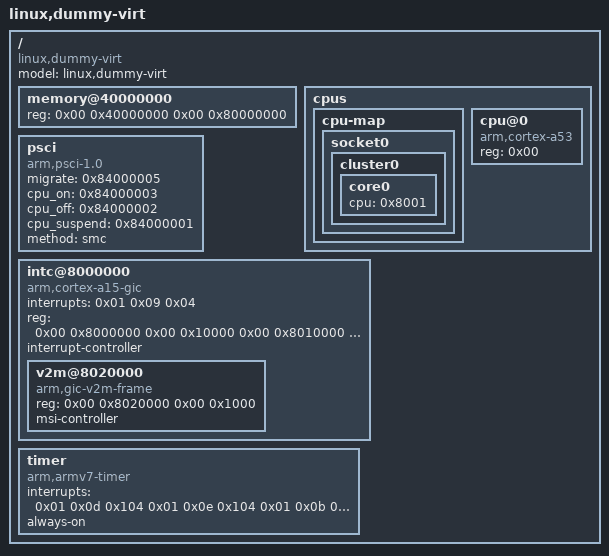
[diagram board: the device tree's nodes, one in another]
/dts-v1/;

/ {
	model = "linux,dummy-virt";
	compatible = "linux,dummy-virt";
	#size-cells = <0x02>;
	#address-cells = <0x02>;


	memory@40000000 {
		reg = <0x00 0x40000000 0x00 0x80000000>;
		device_type = "memory";
	};

	cpus {
		#size-cells = <0x00>;
		#address-cells = <0x01>;

		cpu-map {

			socket0 {

				cluster0 {

					core0 {
						cpu = <0x8001>;
					};
				};
			};
		};

		cpu@0 {
			phandle = <0x8001>;
			reg = <0x00>;
			compatible = "arm,cortex-a53";
			device_type = "cpu";
		};
	};


        psci {
                migrate = <0x84000005>;
                cpu_on = <0x84000003>;
                cpu_off = <0x84000002>;
                cpu_suspend = <0x84000001>;
                method = "smc";
                compatible = "arm,psci-1.0\0arm,psci-0.2\0arm,psci";
       };

	intc@8000000 {
		phandle = <0x8002>;
		interrupts = <0x01 0x09 0x04>;
		reg = <0x00 0x8000000 0x00 0x10000 0x00 0x8010000 0x00 0x10000 0x00 0x8030000 0x00 0x10000 0x00 0x8040000 0x00 0x10000>;
		compatible = "arm,cortex-a15-gic";
		ranges;
		#size-cells = <0x02>;
		#address-cells = <0x02>;
		interrupt-controller;
		#interrupt-cells = <0x03>;

		v2m@8020000 {
			phandle = <0x8003>;
			reg = <0x00 0x8020000 0x00 0x1000>;
			msi-controller;
			compatible = "arm,gic-v2m-frame";
		};
	};
	timer {
		interrupts = <0x01 0x0d 0x104 0x01 0x0e 0x104 0x01 0x0b 0x104 0x01 0x0a 0x104>;
		always-on;
		compatible = "arm,armv7-timer";
	};


};
